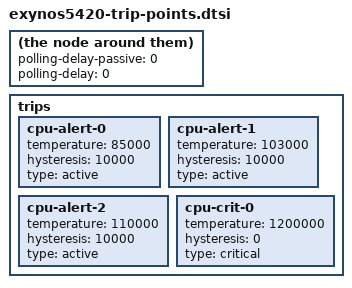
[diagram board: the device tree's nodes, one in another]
/*
 * Device tree sources for default Exynos5420 thermal zone definition
 *
 * Copyright (c) 2014 Lukasz Majewski <l.majewski@samsung.com>
 *
 * This program is free software; you can redistribute it and/or modify
 * it under the terms of the GNU General Public License version 2 as
 * published by the Free Software Foundation.
 *
 */

polling-delay-passive = <0>;
polling-delay = <0>;
trips {
	cpu-alert-0 {
		temperature = <85000>; /* millicelsius */
		hysteresis = <10000>; /* millicelsius */
		type = "active";
	};
	cpu-alert-1 {
		temperature = <103000>; /* millicelsius */
		hysteresis = <10000>; /* millicelsius */
		type = "active";
	};
	cpu-alert-2 {
		temperature = <110000>; /* millicelsius */
		hysteresis = <10000>; /* millicelsius */
		type = "active";
	};
	cpu-crit-0 {
		temperature = <1200000>; /* millicelsius */
		hysteresis = <0>; /* millicelsius */
		type = "critical";
	};
};
